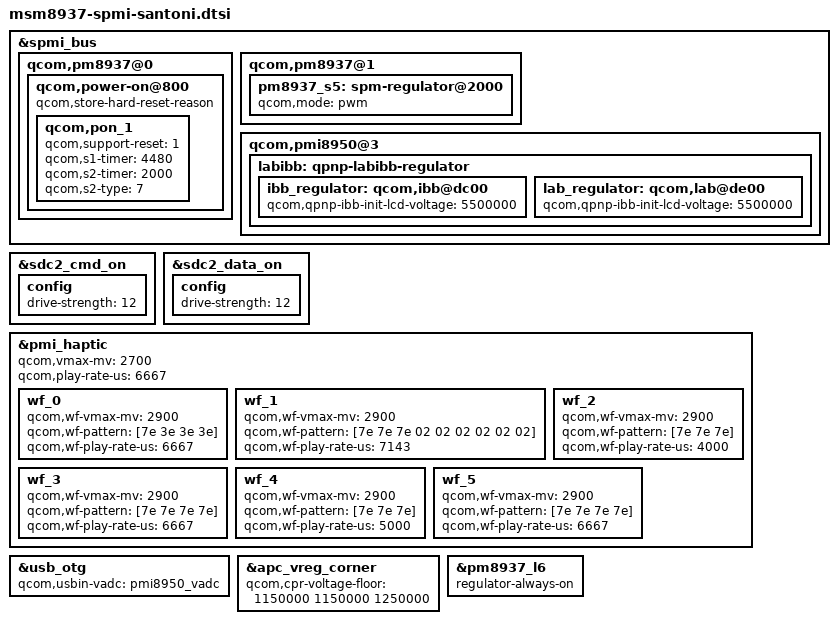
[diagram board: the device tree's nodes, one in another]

&spmi_bus {
	qcom,pm8937@0 {
		qcom,power-on@800 {
			qcom,store-hard-reset-reason;
			qcom,pon_1 {
				qcom,support-reset = <1>;
                                qcom,s1-timer = <4480>;
				qcom,s2-timer = <2000>;
				qcom,s2-type = <7>;
			};
		};
	};

	qcom,pm8937@1 {
		pm8937_s5: spm-regulator@2000 {
			qcom,mode = "pwm";
		};
	};

	qcom,pmi8950@3 {
		labibb: qpnp-labibb-regulator {
			ibb_regulator: qcom,ibb@dc00 {
				/delete-property/
					qcom,qpnp-ibb-use-default-voltage;
				qcom,qpnp-ibb-init-lcd-voltage = <5500000>;
			};

			lab_regulator: qcom,lab@de00 {
				/delete-property/
					qcom,qpnp-ibb-use-default-voltage;
				qcom,qpnp-ibb-init-lcd-voltage = <5500000>;
			};
		};
	};
};

&sdc2_cmd_on {
	config {
		drive-strength = <12>;
	};
};

&sdc2_data_on {
	config {
		drive-strength = <12>;
	};
};

&pmi_haptic {
	status = "okay";
	qcom,vmax-mv = <2700>;
	qcom,play-rate-us = <6667>;
	wf_0 {
		qcom,wf-vmax-mv = <2900>;
		qcom,wf-pattern = [7e 3e 3e 3e];
		qcom,wf-play-rate-us = <6667>;
	};
	wf_1 {
		qcom,wf-vmax-mv = <2900>;
		qcom,wf-pattern = [7e 7e 7e 02 02 02 02 02 02];
		qcom,wf-play-rate-us = <7143>;
	};
	wf_2 {
		qcom,wf-vmax-mv = <2900>;
		qcom,wf-pattern = [7e 7e 7e];
		qcom,wf-play-rate-us = <4000>;
	};
	wf_3 {
		qcom,wf-vmax-mv = <2900>;
		qcom,wf-pattern = [7e 7e 7e 7e];
		qcom,wf-play-rate-us = <6667>;
	};
	wf_4 {
		qcom,wf-vmax-mv = <2900>;
		qcom,wf-pattern = [7e 7e 7e];
		qcom,wf-play-rate-us = <5000>;
	};
	wf_5 {
		qcom,wf-vmax-mv = <2900>;
		qcom,wf-pattern = [7e 7e 7e 7e];
		qcom,wf-play-rate-us = <6667>;
	};
};

&usb_otg {
	qcom,usbin-vadc = <&pmi8950_vadc>;
};

&apc_vreg_corner {
	qcom,cpr-voltage-floor = <1150000 1150000 1250000>;
	/delete-property/ qcom.cpr-enable;
};

&pm8937_l6 {
	regulator-always-on;
};

